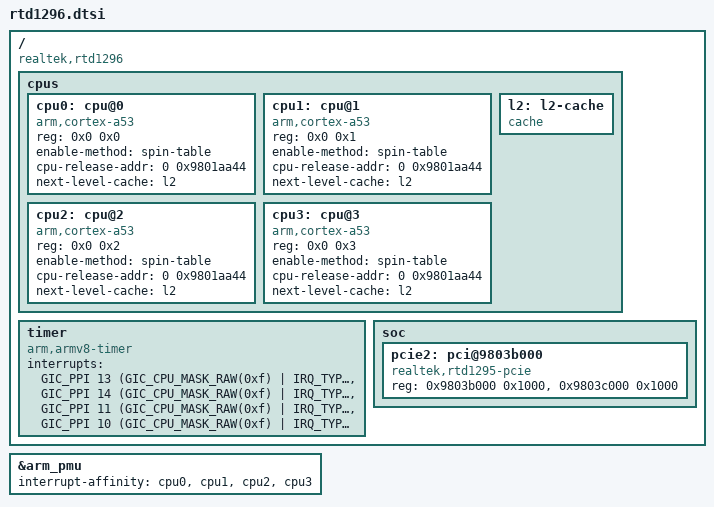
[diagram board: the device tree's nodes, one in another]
/*
 * Realtek RTD1296 SoC
 *
 * Copyright (c) 2017 Andreas Färber
 *
 * SPDX-License-Identifier: (GPL-2.0+ OR MIT)
 */

#include "rtd129x.dtsi"
#include "rtd129x-sata.dtsi"

/ {
	compatible = "realtek,rtd1296";

	cpus {
		#address-cells = <2>;
		#size-cells = <0>;

		cpu0: cpu@0 {
			device_type = "cpu";
			compatible = "arm,cortex-a53", "arm,armv8";
			reg = <0x0 0x0>;
			enable-method = "spin-table";
			cpu-release-addr = <0 0x9801aa44>;
			next-level-cache = <&l2>;
		};

		cpu1: cpu@1 {
			device_type = "cpu";
			compatible = "arm,cortex-a53", "arm,armv8";
			reg = <0x0 0x1>;
			enable-method = "spin-table";
			cpu-release-addr = <0 0x9801aa44>;
			next-level-cache = <&l2>;
		};

		cpu2: cpu@2 {
			device_type = "cpu";
			compatible = "arm,cortex-a53", "arm,armv8";
			reg = <0x0 0x2>;
			enable-method = "spin-table";
			cpu-release-addr = <0 0x9801aa44>;
			next-level-cache = <&l2>;
		};

		cpu3: cpu@3 {
			device_type = "cpu";
			compatible = "arm,cortex-a53", "arm,armv8";
			reg = <0x0 0x3>;
			enable-method = "spin-table";
			cpu-release-addr = <0 0x9801aa44>;
			next-level-cache = <&l2>;
		};

		l2: l2-cache {
			compatible = "cache";
		};
	};

	timer {
		compatible = "arm,armv8-timer";
		interrupts = <GIC_PPI 13
			(GIC_CPU_MASK_RAW(0xf) | IRQ_TYPE_LEVEL_LOW)>,
			     <GIC_PPI 14
			(GIC_CPU_MASK_RAW(0xf) | IRQ_TYPE_LEVEL_LOW)>,
			     <GIC_PPI 11
			(GIC_CPU_MASK_RAW(0xf) | IRQ_TYPE_LEVEL_LOW)>,
			     <GIC_PPI 10
			(GIC_CPU_MASK_RAW(0xf) | IRQ_TYPE_LEVEL_LOW)>;
	};

	soc {
		pcie2: pci@9803b000 {
			compatible = "realtek,rtd1295-pcie";
			reg = <0x9803b000 0x1000>,
			      <0x9803c000 0x1000>;
		};
	};
};

&arm_pmu {
	interrupt-affinity = <&cpu0>, <&cpu1>, <&cpu2>, <&cpu3>;
};
